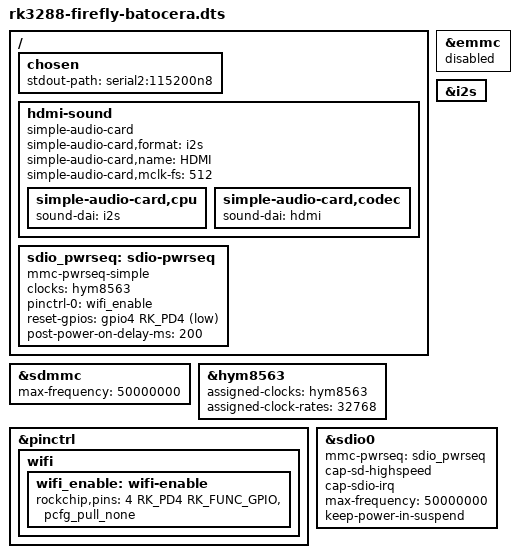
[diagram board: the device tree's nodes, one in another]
// SPDX-License-Identifier: (GPL-2.0+ OR MIT)
// Firefly-RK3288 original board: Batocera 39 HDMI + microSD bring-up.
#include "rk3288-firefly.dts"

/ {
    chosen {
        stdout-path = "serial2:115200n8";
    };

    hdmi-sound {
        compatible = "simple-audio-card";
        simple-audio-card,format = "i2s";
        simple-audio-card,name = "HDMI";
        simple-audio-card,mclk-fs = <512>;

        simple-audio-card,cpu {
            sound-dai = <&i2s>;
        };
        simple-audio-card,codec {
            sound-dai = <&hdmi>;
        };
    };

    sdio_pwrseq: sdio-pwrseq {
        compatible = "mmc-pwrseq-simple";
        clocks = <&hym8563>;
        clock-names = "ext_clock";
        pinctrl-names = "default";
        pinctrl-0 = <&wifi_enable>;
        reset-gpios = <&gpio4 RK_PD4 GPIO_ACTIVE_LOW>;
        post-power-on-delay-ms = <200>;
    };
};

// This first bring-up image exposes only microSD to Linux.
&emmc {
    status = "disabled";
};

&i2s {
    #sound-dai-cells = <0>;
    status = "okay";
};

&sdmmc {
    max-frequency = <50000000>;
};

&hym8563 {
    assigned-clocks = <&hym8563>;
    assigned-clock-rates = <32768>;
};

&pinctrl {
    wifi {
        wifi_enable: wifi-enable {
            rockchip,pins = <4 RK_PD4 RK_FUNC_GPIO &pcfg_pull_none>;
        };
    };
};

&sdio0 {
    // The inherited vbat_wl alias points at the shared 5 V vcc_sys rail,
    // outside MMC OCR voltages. The module has a fixed external supply;
    // do not request voltage changes on that rail. Keep the 1.8 V IO supply.
    /delete-property/ vmmc-supply;
    mmc-pwrseq = <&sdio_pwrseq>;
    cap-sd-highspeed;
    cap-sdio-irq;
    max-frequency = <50000000>;
    keep-power-in-suspend;
};
